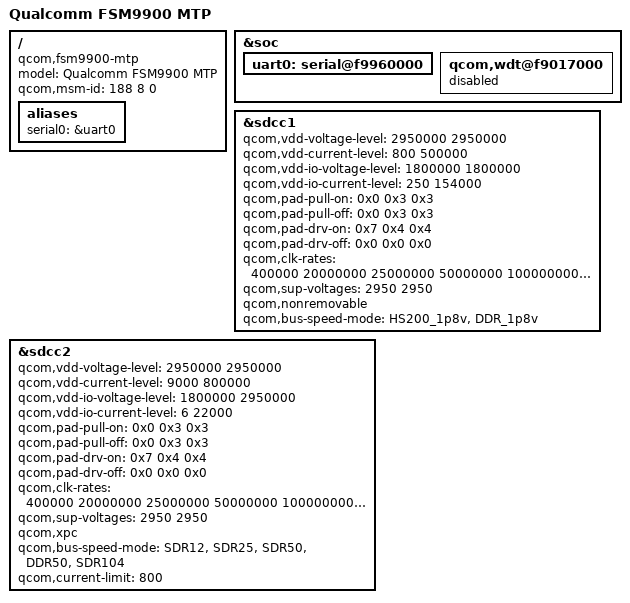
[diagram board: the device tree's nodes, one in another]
/* Copyright (c) 2013, The Linux Foundation. All rights reserved.
 *
 * This program is free software; you can redistribute it and/or modify
 * it under the terms of the GNU General Public License version 2 and
 * only version 2 as published by the Free Software Foundation.
 *
 * This program is distributed in the hope that it will be useful,
 * but WITHOUT ANY WARRANTY; without even the implied warranty of
 * MERCHANTABILITY or FITNESS FOR A PARTICULAR PURPOSE.  See the
 * GNU General Public License for more details.
 */

/dts-v1/;

/include/ "fsm9900.dtsi"

/ {
	model = "Qualcomm FSM9900 MTP";
	compatible = "qcom,fsm9900-mtp", "qcom,fsm9900", "qcom,mtp";
	qcom,msm-id = <188 8 0>;

	aliases {
		serial0 = &uart0;
	};
};

&soc {
	uart0: serial@f9960000 {
		status = "ok";
	};

	qcom,wdt@f9017000 {
		status = "disabled";
	};

};


&sdcc1 {
	qcom,vdd-voltage-level = <2950000 2950000>;
	qcom,vdd-current-level = <800 500000>;

	qcom,vdd-io-voltage-level = <1800000 1800000>;
	qcom,vdd-io-current-level = <250 154000>;

	qcom,pad-pull-on = <0x0 0x3 0x3>; /* no-pull, pull-up, pull-up */
	qcom,pad-pull-off = <0x0 0x3 0x3>; /* no-pull, pull-up, pull-up */
	qcom,pad-drv-on = <0x7 0x4 0x4>; /* 16mA, 10mA, 10mA */
	qcom,pad-drv-off = <0x0 0x0 0x0>; /* 2mA, 2mA, 2mA */

	qcom,clk-rates = <400000 20000000 25000000 50000000 100000000 200000000>;
	qcom,sup-voltages = <2950 2950>;
	qcom,nonremovable;
	qcom,bus-speed-mode = "HS200_1p8v", "DDR_1p8v";

	status = "ok";
};

&sdcc2 {
	qcom,vdd-voltage-level = <2950000 2950000>;
	qcom,vdd-current-level = <9000 800000>;
	qcom,vdd-io-voltage-level = <1800000 2950000>;
	qcom,vdd-io-current-level = <6 22000>;

	qcom,pad-pull-on = <0x0 0x3 0x3>; /* no-pull, pull-up, pull-up */
	qcom,pad-pull-off = <0x0 0x3 0x3>; /* no-pull, pull-up, pull-up */
	qcom,pad-drv-on = <0x7 0x4 0x4>; /* 16mA, 10mA, 10mA */
	qcom,pad-drv-off = <0x0 0x0 0x0>; /* 2mA, 2mA, 2mA */

	qcom,clk-rates = <400000 20000000 25000000 50000000 100000000 200000000>;
	qcom,sup-voltages = <2950 2950>;
	qcom,xpc;
	qcom,bus-speed-mode = "SDR12", "SDR25", "SDR50", "DDR50", "SDR104";
	qcom,current-limit = <800>;

	status = "ok";
};
